# GD32F50x register map
File version: 1.0
CPU: CM33 r2p1, little endian, MPU, FPU, 4 interrupt priority bits
Registers are 32-bit, read-write, reset 0x0 unless marked. A register's access mark holds for its fields unless they carry their own. Offsets are from the block's base; [hi:lo] are bit positions; {n}, {i} and the like mark numbered series.

## FWDGT — free watchdog timer
Base 0x40003000
0x00 CTL wo — Control register
  [15:0] CMD — Key value
0x04 PSC — Prescaler register
  [2:0] PSC — Free watchdog timer prescaler selection
0x08 RLD reset 0xFFF — Reload register
  [11:0] RLD — Free watchdog timer counter reload value
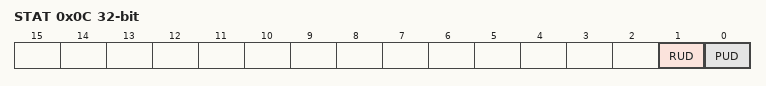
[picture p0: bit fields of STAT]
0x0C STAT ro — Status register
  [1] RUD — Free watchdog timer counter reload value update
  [0] PUD — Free watchdog timer prescaler value update

## GPIOA — General-purpose I/Os
Base 0x40010800
Same registers: GPIOB 0x40010C00, GPIOC 0x40011000, GPIOD 0x40011400, GPIOE 0x40011800
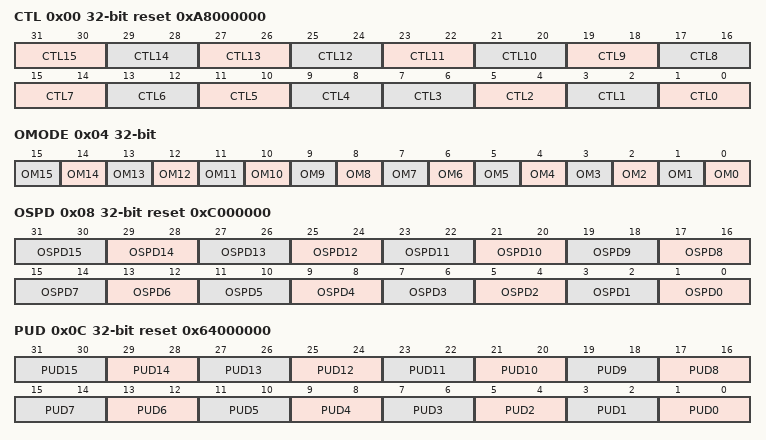
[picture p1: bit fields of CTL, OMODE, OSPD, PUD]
0x00 CTL reset 0xA8000000 — GPIO port control register
  [2n+1:2n] CTL{n} (n=7..15) — Port x configuration bits (x = {n})
  [13:12] CTL6 — Port x configuration bits (x = 6 )
  [11:10] CTL5 — Port x configuration bits (x = 5)
  [9:8] CTL4 — Port x configuration bits (x = 4 )
  [2n+1:2n] CTL{n} (n=0..3) — Port x configuration bits (x = {n})
0x04 OMODE — GPIO port output mode register
  [n] OM{n} (n=0..15) — Port {n} output mode bit
0x08 OSPD reset 0xC000000 — GPIO port output speed register
  [2n+1:2n] OSPD{n} (n=0..15) — Port {n} output max speed bits
0x0C PUD reset 0x64000000 — GPIO port pull-up/pull-down register
  [2n+1:2n] PUD{n} (n=0..15) — Port {n} pull-up or pull-down bits
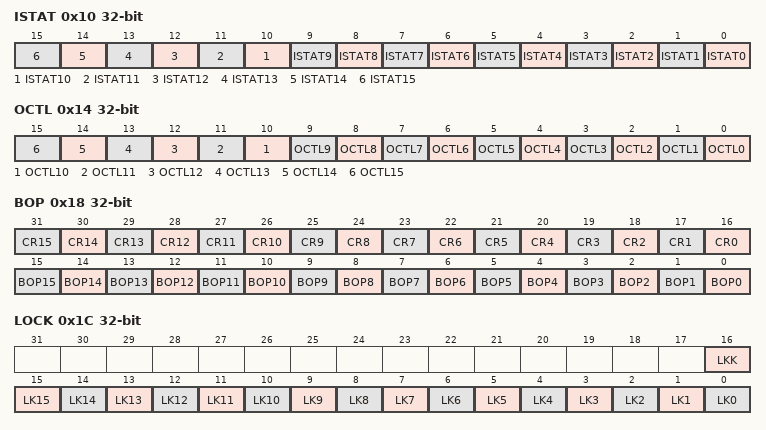
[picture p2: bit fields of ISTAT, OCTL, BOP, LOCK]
0x10 ISTAT ro — GPIO port input status register
  [n] ISTAT{n} (n=0..15) — Port input status (y = {n})
0x14 OCTL — GPIO port output control register
  [n] OCTL{n} (n=0..15) — Port output control (y = {n})
0x18 BOP wo — GPIO port bit operate register
  [n+16] CR{n} (n=0..15) — Port Clear bit {n}
  [n] BOP{n} (n=0..15) — Port Set bit {n}
0x1C LOCK — GPIO port configuration lock register
  [16] LKK — Lock sequence key
  [n] LK{n} (n=0..15) — Port Lock bit {n}
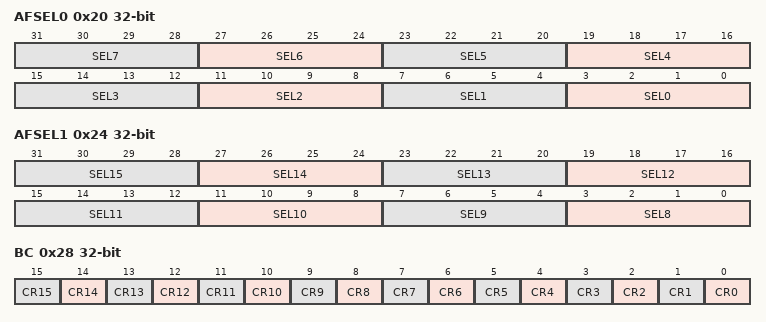
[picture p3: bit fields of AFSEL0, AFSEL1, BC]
0x20 AFSEL0 — GPIO alternate function selected register 0
  [4n+3:4n] SEL{n} (n=0..7) — Port {n} alternate function selected
0x24 AFSEL1 — GPIO alternate function selected register 1
  [4n-29:4n-32] SEL{n} (n=8..15) — Port {n} alternate function selected
0x28 BC wo — Bit clear register
  [n] CR{n} (n=0..15) — Port cleat bit

## PMU — Power management unit
Base 0x40007000
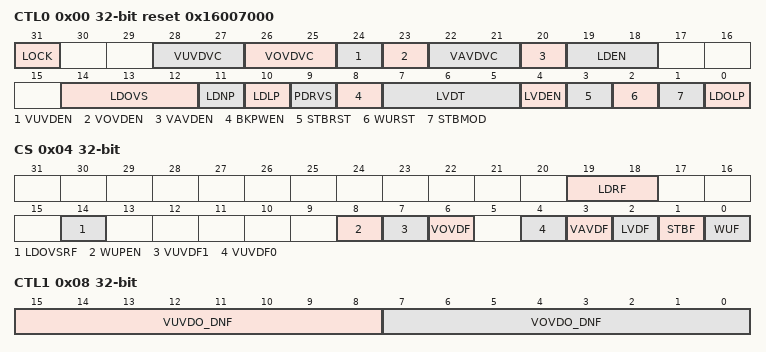
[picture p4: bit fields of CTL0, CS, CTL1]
0x00 CTL0 reset 0x16007000 — Control register0
  [31] LOCK
  [28:27] VUVDVC — V1.2v under voltage detector voltage level configure bits
  [26:25] VOVDVC — V1.2v over voltage detector voltage level configure bits
  [24] VUVDEN — V1.2V under Voltage detector enable
  [23] VOVDEN — V1.2V over Voltage detector enable
  [22:21] VAVDVC — VDDA analog voltage detector voltage level configure bits
  [20] VAVDEN — VDDA analog voltage detector voltage enable bit
  [19:18] LDEN — Low-driver mode enable in Deep-sleep mode
  [14:12] LDOVS — LDO output voltage select
  [11] LDNP — Low-driver mode when use normal power LDO
  [10] LDLP — Low-driver mode when use low power LDO.
  [9] PDRVS — PDR threshold selection
  [8] BKPWEN — Backup Domain Write Enable
  [7:5] LVDT — Low Voltage Detector Threshold
  [4] LVDEN — Low Voltage Detector Enable
  [3] STBRST — Standby Flag Reset
  [2] WURST — Wakeup Flag Reset
  [1] STBMOD — Standby Mode
  [0] LDOLP — LDO Low Power Mode
0x04 CS access per field — Control and status register
  [19:18] LDRF rw — Low-driver mode ready flag
  [14] LDOVSRF ro — LDO voltage select ready flag
  [8] WUPEN rw — WKUP Pin Enable
  [7] VUVDF1 ro — V1.2v under voltage detector flag bit after digital filter.
  [6] VOVDF ro — V1.2v over voltage detector flag bit after digital filter.
  [4] VUVDF0 ro — V1.2v under voltage detector flag bit
  [3] VAVDF ro — VDDA analog voltage detector voltage output on VDDA flag bit.
  [2] LVDF ro — Low Voltage Detector Status Flag
  [1] STBF ro — Standby Flag
  [0] WUF ro — Wakeup Flag
0x08 CTL1 — Control register
  [15:8] VUVDO_DNF — VUVD analog output digital noise filter
  [7:0] VOVDO_DNF — VOVD analog output digital noise filter
